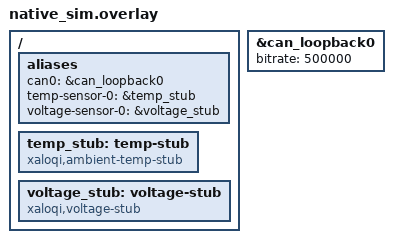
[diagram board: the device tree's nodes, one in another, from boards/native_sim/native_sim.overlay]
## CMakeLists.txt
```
# examples/sensor_ecu/CMakeLists.txt
# =============================================================================
# Xaloqi EDS — SensorECU example
# Zephyr zone controller with real sensor integration.
#
# BUILDING:
#   # Simulation build (CI / host testing, no hardware required):
#   # [EDS#339] -DEXTRA_CONF_FILE/-DDTC_OVERLAY_FILE must be passed
#   # explicitly — this example's own boards/native_sim/native_sim.conf
#   # and .overlay (nested) are never auto-discovered by Zephyr (only a
#   # flat boards/<board>.conf is — same gap O-132 found and documented
#   # for examples/bms_ecu/CMakeLists.txt). Omitting them silently builds
#   # without CONFIG_SENSOR/CONFIG_REBOOT and without the sensor devicetree
#   # nodes at all, rather than failing the way EDS#339 describes.
#   west build -b native_sim examples/sensor_ecu \
#     -- -DDIAG_SKIP_CODEGEN=ON \
#     -DEXTRA_CONF_FILE=<eds>/examples/sensor_ecu/boards/native_sim/native_sim.conf \
#     -DDTC_OVERLAY_FILE=<eds>/examples/sensor_ecu/boards/native_sim/native_sim.overlay
# =============================================================================

cmake_minimum_required(VERSION 3.20.0)

# [EDS#339] Out-of-tree devicetree bindings for the native_sim-only stub
# sensor driver (drivers/sensor_stub/) — must be appended before
# find_package(Zephyr) parses devicetree.
list(APPEND DTS_ROOT ${CMAKE_CURRENT_SOURCE_DIR})

# [#414] EDS Kconfig comes from this tree, not whichever EDS module the
# workspace has. Must precede find_package(Zephyr).
include(${CMAKE_CURRENT_SOURCE_DIR}/../../cmake/eds_zephyr_module.cmake)

find_package(Zephyr REQUIRED HINTS $ENV{ZEPHYR_BASE})

project(sensor_ecu
    VERSION     1.0.0
    LANGUAGES   C
    DESCRIPTION "SensorECU — Xaloqi EDS sensor integration example"
)

set(CMAKE_C_STANDARD          11)
set(CMAKE_C_STANDARD_REQUIRED ON)
set(CMAKE_C_EXTENSIONS        OFF)

# [#515] -Wundef (MISRA 20.9) below applies to EDS code only: Zephyr, module and
# HAL headers are system includes for this target. See the cmake file.
include(${CMAKE_CURRENT_SOURCE_DIR}/../../cmake/eds_third_party_headers.cmake)
eds_third_party_headers_are_system(app)

target_compile_options(app PRIVATE
    -Wall -Wextra -Wshadow -Wdouble-promotion -Wundef
    -Wno-unused-parameter -Wno-sign-conversion
    -fstack-usage
)

# ---------------------------------------------------------------------------
# Paths
# ---------------------------------------------------------------------------

set(DIAG_ROOT          "${CMAKE_CURRENT_SOURCE_DIR}/../..")
set(DIAG_CONFIG_YAML   "${CMAKE_CURRENT_SOURCE_DIR}/diagnostics_config.yaml")
set(DIAG_CODEGEN_SCRIPT "${DIAG_ROOT}/tools/codegen.py")
set(DIAG_GENERATED_DIR  "${CMAKE_CURRENT_SOURCE_DIR}/generated")
set(CODEGEN_SENTINEL    "${DIAG_GENERATED_DIR}/generated_config.h")

# [EDS#339] Defaulted ON for this example (the one difference from most
# other examples' CMakeLists.txt pattern, shared with vehicle_state_ecu).
# generated/did_handlers.c and generated/routine_handlers.c carry
# hand-written [APP HOOK] bodies that delegate to sensor_monitor.c's real
# state — did_entry_t.read_cb/write_cb and routine_entry_t's callbacks are
# bare function pointers copied by value into a fixed-capacity array at
# init (did_database_register()/routine_database_register()), so there is
# no way to re-point them at runtime; the callback bodies in the
# generated files are the only place this application's live behaviour
# can run. Re-running codegen would silently overwrite them with empty
# TODO stubs — the guard below fails loudly, at configure time, if that
# ever happens without the hooks being reapplied.
option(DIAG_SKIP_CODEGEN "Skip auto-running codegen (use existing generated/ files)" ON)

# ---------------------------------------------------------------------------
# Code generation
# ---------------------------------------------------------------------------

if(NOT DIAG_SKIP_CODEGEN)
    find_package(Python3 COMPONENTS Interpreter QUIET)
    if(NOT Python3_FOUND)
        message(FATAL_ERROR "Python3 not found. Install it or use -DDIAG_SKIP_CODEGEN=ON")
    endif()

    file(GLOB DIAG_TEMPLATES "${DIAG_ROOT}/tools/templates/*.j2")

    add_custom_command(
        OUTPUT   "${CODEGEN_SENTINEL}"
        COMMAND  "${Python3_EXECUTABLE}"
                 "${DIAG_CODEGEN_SCRIPT}"
                 --config "${DIAG_CONFIG_YAML}"
                 --out    "${DIAG_GENERATED_DIR}"
                 --safety-wrappers --asil-level B
                 --no-manifest
        DEPENDS
            "${DIAG_CONFIG_YAML}"
            "${DIAG_CODEGEN_SCRIPT}"
            ${DIAG_TEMPLATES}
        COMMENT "[sensor_ecu] Generating sources from diagnostics_config.yaml... "
                "NOTE: this will overwrite the hand-written [APP HOOK] bodies in "
                "generated/did_handlers.c and generated/routine_handlers.c -- "
                "reapply them before committing."
        VERBATIM
    )

    add_custom_target(run_codegen DEPENDS "${CODEGEN_SENTINEL}")
endif()

# ---------------------------------------------------------------------------
# Include paths
# ---------------------------------------------------------------------------

target_include_directories(app PRIVATE
    ${DIAG_ROOT}/core
    ${DIAG_ROOT}/core/uds_services
    ${DIAG_ROOT}/transport
    ${DIAG_ROOT}/config
    ${DIAG_ROOT}/platform
    ${DIAG_ROOT}/platform/zephyr
    ${DIAG_GENERATED_DIR}
    ${CMAKE_CURRENT_SOURCE_DIR}/src   # sensor_ecu.h
)

# ---------------------------------------------------------------------------
# Sources
# ---------------------------------------------------------------------------

# UDS service source list — set EDS_SERVICE_SRCS.
include(${DIAG_ROOT}/cmake/eds_service_sources.cmake)

target_sources(app PRIVATE

    # Application
    ${CMAKE_CURRENT_SOURCE_DIR}/src/main.c
    ${CMAKE_CURRENT_SOURCE_DIR}/src/sensor_monitor.c

    # [EDS#339] native_sim-only stub sensor driver backing the devicetree
    # nodes in boards/native_sim/native_sim.overlay (DTS_ROOT above).
    # Harmless to compile unconditionally: DEVICE_DT_INST_DEFINE expands
    # to nothing if no "xaloqi,ambient-temp-stub"/"xaloqi,voltage-stub"
    # node is status "okay" for the board being built.
    ${CMAKE_CURRENT_SOURCE_DIR}/drivers/sensor_stub/ambient_temp_stub.c
    ${CMAKE_CURRENT_SOURCE_DIR}/drivers/sensor_stub/voltage_stub.c

    # [#333] src/did_handlers_impl.c is deliberately NOT listed. It does not
    # exist in this example (only in sensor_ecu_freertos), and the generated
    # did_handlers.c below already defines did_handlers_register_all() and
    # s_did_table — listing both would be a duplicate-symbol link failure.
    # See sensor_ecu_freertos/CMakeLists.txt for the same hazard documented.

    # UDS core
    ${DIAG_ROOT}/core/uds_server.c
    ${DIAG_ROOT}/core/uds_session.c
    ${DIAG_ROOT}/core/uds_security.c
    ${DIAG_ROOT}/core/uds_safety.c
    ${DIAG_ROOT}/core/uds_security_algo.c
    ${DIAG_ROOT}/core/uds_access_table.c
    ${DIAG_ROOT}/core/uds_comm_control.c
    ${DIAG_ROOT}/core/uds_session_stats.c
    ${DIAG_ROOT}/core/uds_security_nvm.c
    ${DIAG_ROOT}/core/uds_aes_cmac.c
    ${DIAG_ROOT}/core/uds_transfer_ctx.c

    # UDS service handlers (all 16 SIDs + dispatch table).
    ${EDS_SERVICE_SRCS}

    # ISO-TP + CAN
    ${DIAG_ROOT}/transport/isotp.c
    ${DIAG_ROOT}/transport/can_transport.c
    ${DIAG_ROOT}/platform/zephyr/zephyr_can.c  # moved from transport/ — phase-housekeeping

    # Config databases
    ${DIAG_ROOT}/config/did_database.c
    ${DIAG_ROOT}/config/dtc_database.c
    ${DIAG_ROOT}/config/dtc_mirror.c
    ${DIAG_ROOT}/config/routine_database.c

    # Platform
    ${DIAG_ROOT}/platform/uds_flash_ops.c
    ${DIAG_ROOT}/platform/uds_image_policy.c  # [#232] Image verification policy singleton
    ${DIAG_ROOT}/platform/zephyr/zephyr_port.c
    ${DIAG_ROOT}/platform/zephyr/zephyr_mutex.c
    ${DIAG_ROOT}/platform/zephyr/zephyr_timer.c
    ${DIAG_ROOT}/platform/zephyr/zephyr_wdt.c
    ${DIAG_ROOT}/platform/zephyr/zephyr_platform_api.c

    # Generated
    ${DIAG_GENERATED_DIR}/did_handlers.c
    ${DIAG_GENERATED_DIR}/uds_init.c
    ${DIAG_GENERATED_DIR}/did_safety_wrappers.c
    ${DIAG_GENERATED_DIR}/routine_handlers.c
)

# NVM store — mock on native_sim, real NVS on hardware
if(CONFIG_BOARD_NATIVE_SIM)
    target_sources(app PRIVATE ${DIAG_ROOT}/platform/zephyr/nvm_store_mock.c)
else()
    target_sources(app PRIVATE ${DIAG_ROOT}/platform/zephyr/nvm_store.c)
endif()

if(NOT DIAG_SKIP_CODEGEN AND TARGET run_codegen)
    add_dependencies(app run_codegen)
endif()

# ---------------------------------------------------------------------------
# [APP HOOK] guard — fail loudly, at configure time, if generated/
# did_handlers.c or generated/routine_handlers.c were ever regenerated
# without reapplying the hand-written delegations to sensor_monitor.c.
# ---------------------------------------------------------------------------
file(STRINGS "${DIAG_GENERATED_DIR}/did_handlers.c" DIAG_DID_APP_HOOK_LINES
     REGEX "\\[APP HOOK\\]")
list(LENGTH DIAG_DID_APP_HOOK_LINES DIAG_DID_APP_HOOK_COUNT)
if(DIAG_DID_APP_HOOK_COUNT LESS 5)
    message(FATAL_ERROR
        "\n"
        "[sensor_ecu] ERROR: generated/did_handlers.c is missing its\n"
        "       [APP HOOK] markers (found ${DIAG_DID_APP_HOOK_COUNT}, expected >= 5).\n"
        "       This file was regenerated and the hand-written delegations to\n"
        "       sensor_monitor.c were lost. See EDS#339 and reapply them\n"
        "       before building.\n"
    )
endif()

file(STRINGS "${DIAG_GENERATED_DIR}/routine_handlers.c" DIAG_RTN_APP_HOOK_LINES
     REGEX "\\[APP HOOK\\]")
list(LENGTH DIAG_RTN_APP_HOOK_LINES DIAG_RTN_APP_HOOK_COUNT)
if(DIAG_RTN_APP_HOOK_COUNT LESS 2)
    message(FATAL_ERROR
        "\n"
        "[sensor_ecu] ERROR: generated/routine_handlers.c is missing its\n"
        "       [APP HOOK] markers (found ${DIAG_RTN_APP_HOOK_COUNT}, expected >= 2).\n"
        "       This file was regenerated and the hand-written delegations to\n"
        "       sensor_monitor.c were lost. See EDS#339 and reapply them\n"
        "       before building.\n"
    )
endif()

# Suppress the uds_msg_buf_t _Static_assert for all Zephyr example builds.
# The Zephyr task stacks for these examples (4096-6144 bytes) are large enough
# to hold the struct if needed, but all EDS stack buffers are module-level
# statics — the assert would fire as a false positive on every compilation unit.
# Zephyr's native_sim gets this via the CMakeLists.txt native_sim block;
# hardware targets need it here.
target_compile_definitions(app PRIVATE EDS_MSG_BUF_MAX_STACK_BYTES=8192)
```

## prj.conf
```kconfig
# examples/sensor_ecu/prj.conf
# Base configuration for all board targets.
# Board-specific overrides in boards/<board>/<board>.conf

# --- CAN driver ---
CONFIG_CAN=y
CONFIG_CAN_INIT_PRIORITY=80
CONFIG_STATS=y
CONFIG_CAN_STATS=y

# --- Sensor subsystem ---
CONFIG_SENSOR=y
CONFIG_I2C=y

# --- Kernel / threading ---
CONFIG_MULTITHREADING=y
CONFIG_THREAD_STACK_INFO=y
CONFIG_THREAD_NAME=y

# --- Tick rate: 1 ms for ISO-TP ---
CONFIG_SYS_CLOCK_TICKS_PER_SEC=1000
CONFIG_TICKLESS_KERNEL=n

# --- Watchdog ---
CONFIG_WATCHDOG=y
CONFIG_WDT_DISABLE_AT_BOOT=n
CONFIG_DIAG_WDT_WINDOW_MS=100

# --- Logging ---
CONFIG_LOG=y
CONFIG_LOG_DEFAULT_LEVEL=3
CONFIG_LOG_BACKEND_UART=y
CONFIG_LOG_BUFFER_SIZE=2048

# --- Safety hardening ---
CONFIG_ASSERT=y
CONFIG_STACK_CANARIES=y
# Fail the build if the canaries are not real (see Kconfig EDS_REQUIRE_STACK_CANARIES).
CONFIG_EDS_REQUIRE_STACK_CANARIES=y
CONFIG_STACK_SENTINEL=y

# --- No heap (MISRA-21.3) ---
CONFIG_HEAP_MEM_POOL_SIZE=0

# --- C library ---
CONFIG_NEWLIB_LIBC=y
# [#498] Fail the build, rather than silently link picolibc, if newlib is unavailable.
CONFIG_EDS_REQUIRE_NEWLIB=y

# --- UDS session timing / SecurityAccess lockout: diagnostics_config.yaml (EDS#455);
#     ISO-TP timeouts: EDS defaults, ISO 15765-2:2024 1000 ms (EDS#453) ---

# --- Task stack sizes ---
CONFIG_DIAG_TASK_STACK_SIZE=4096
CONFIG_DIAG_TASK_PRIORITY=5

# --- Build output ---
CONFIG_BUILD_OUTPUT_BIN=y
CONFIG_BUILD_OUTPUT_HEX=y
```

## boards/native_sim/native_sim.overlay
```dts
/*
 * =============================================================================
 * Xaloqi EDS
 * boards/native_sim/native_sim.overlay
 * examples/sensor_ecu/
 *
 * Device Tree overlay for native_sim (host simulation).
 *
 * Provides:
 *   - CAN loopback (same as all other examples)
 *   - Two stub sensor nodes, backed by a minimal out-of-tree driver that
 *     ships with this example (drivers/sensor_stub/, bound via
 *     dts/bindings/sensor/ -- see CMakeLists.txt's DTS_ROOT addition).
 *     [EDS#339] These return fixed nominal readings; native_sim has no
 *     physical sensor to simulate, and DTC firing/clearing is
 *     demonstrated via extreme thresholds (DID 0xD010/0xD011), not by
 *     varying the reading -- see sensor_monitor.c's header comment.
 *
 * On real hardware, replace these nodes with your physical sensor:
 *
 *   Temperature sensor examples:
 *     SHTC3 (I2C):   compatible = "sensirion,shtc3";
 *     LM75A (I2C):   compatible = "lm75";
 *     MCP9808 (I2C): compatible = "microchip,mcp9808";
 *     NTC on ADC:    compatible = "ntc-thermistor-generic";
 *
 *   Voltage sensor examples:
 *     INA219 (I2C):  compatible = "ti,ina219";
 *     ADC divider:   compatible = "voltage-divider";
 *
 * The aliases (temp-sensor-0, voltage-sensor-0) are the only coupling
 * between sensor_monitor.c and the board DTS. Change the alias target
 * to point at your physical sensor node and the application code is
 * unchanged.
 * =============================================================================
 */

/ {
    aliases {
        /* CAN loopback — same as basic_ecu */
        can0 = &can_loopback0;

        /*
         * Sensor aliases — sensor_monitor.c resolves devices by these names.
         * On native_sim: point to stub driver nodes below.
         * On hardware: point to the physical sensor node in your board DTS.
         */
        temp-sensor-0    = &temp_stub;
        voltage-sensor-0 = &voltage_stub;
    };

    /*
     * [EDS#339] Backed by drivers/sensor_stub/ambient_temp_stub.c — fixed
     * 25 degC reading. Previously used compatible = "zephyr,temperature-
     * stub", a string that both claimed in-tree Zephyr provenance it
     * didn't have and had no backing driver at all (undefined reference
     * to __device_dts_ord_N at link time). Renamed to an "xaloqi,"
     * compatible matching the binding this example actually ships.
     */
    temp_stub: temp-stub {
        compatible = "xaloqi,ambient-temp-stub";
        status = "okay";
    };

    /* [EDS#339] Same history and fix as temp_stub above. */
    voltage_stub: voltage-stub {
        compatible = "xaloqi,voltage-stub";
        status = "okay";
    };
};

&can_loopback0 {
    status = "okay";
    bitrate   = <500000>;
};
```

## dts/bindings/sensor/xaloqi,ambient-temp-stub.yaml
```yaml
# Copyright (c) 2026 Xaloqi
# SPDX-License-Identifier: Apache-2.0

description: |
  Xaloqi EDS example-only stub ambient temperature sensor.

  native_sim has no real temperature hardware. This binding backs a
  minimal out-of-tree driver (drivers/sensor_stub/ambient_temp_stub.c)
  that returns a fixed nominal reading so sensor_monitor.c's real Zephyr
  sensor API calls (sensor_sample_fetch/sensor_channel_get) have an
  actual struct device to resolve against on native_sim. On real
  hardware, replace this node with a physical sensor binding (see
  boards/native_sim/native_sim.overlay's header comment for examples) —
  this binding is not meant to be used outside this example.

compatible: "xaloqi,ambient-temp-stub"

include: sensor-device.yaml
```

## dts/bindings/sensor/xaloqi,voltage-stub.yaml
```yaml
# Copyright (c) 2026 Xaloqi
# SPDX-License-Identifier: Apache-2.0

description: |
  Xaloqi EDS example-only stub supply-voltage sensor.

  native_sim has no real voltage-monitoring hardware. This binding backs
  a minimal out-of-tree driver (drivers/sensor_stub/voltage_stub.c) that
  returns a fixed nominal reading so sensor_monitor.c's real Zephyr
  sensor API calls (sensor_sample_fetch/sensor_channel_get) have an
  actual struct device to resolve against on native_sim. On real
  hardware, replace this node with a physical sensor binding (see
  boards/native_sim/native_sim.overlay's header comment for examples) —
  this binding is not meant to be used outside this example.

compatible: "xaloqi,voltage-stub"

include: sensor-device.yaml
```

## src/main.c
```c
/*
 * =============================================================================
 * Xaloqi EDS
 * FILE: examples/sensor_ecu/src/main.c
 *
 * PURPOSE: SensorECU — zone controller with real sensor integration.
 *
 *          Demonstrates the complete Xaloqi EDS sensor pattern:
 *
 *            Zephyr sensor API (temp, voltage)
 *              ↓
 *            sensor_monitor thread (100 ms cycle)
 *              ↓ dtc_database_set_status()
 *            DTC database (0xD00101, 0xD00102, 0xD00201, 0xD00202)
 *              ↓
 *            UDS 0x19 ReadDTCInformation → tester reads active faults
 *            UDS 0x22 ReadDataByIdentifier → tester reads live sensor values
 *
 *          Two threads run concurrently:
 *            diag_task     — 1 ms poll loop (ISO-TP + UDS dispatch)
 *            sensor_monitor — 100 ms sensor read + DTC update
 *
 * THREAD MODEL:
 *   main()
 *     ├─ sensor_monitor_init()   → starts sensor_monitor thread
 *     ├─ uds_generated_init()    → initialises UDS stack
 *     └─ diag task created       → starts diagnostic poll loop
 *
 *   sensor_monitor thread (priority 7, 100 ms sleep):
 *     sensor_sample_fetch() → dtc_database_set_status() → k_mutex_unlock()
 *
 *   diag_task thread (priority 5, 1 ms tick):
 *     can_transport_receive() → isotp_process_rx_frame() → uds_server_process_request()
 *     DID 0xD001/0xD002/0xD003 handlers — generated/did_handlers.c's
 *     [APP HOOK] bodies call sensor_state_get() directly [EDS#339, fixed].
 *     See sensor_monitor.c's header comment for the native_sim driver.
 *
 * SPDX-License-Identifier: Apache-2.0
 * =============================================================================
 */

#include "sensor_ecu.h"
#include "uds_types.h"
#include "uds_server.h"
#include "uds_periodic.h"
#include "uds_session.h"
#include "dtc_database.h"
#include "isotp.h"
#include "can_transport.h"
#include "zephyr_port.h"
#include "zephyr_mutex.h"
#include "zephyr_timer.h"
#include "zephyr_wdt.h"
#include "nvm_store.h"
#include "uds_init.h"
#include "uds_security_algo.h"
#include "generated_config.h"

#include <zephyr/kernel.h>
#include <zephyr/device.h>
#include <zephyr/drivers/can.h>
#include <zephyr/logging/log.h>

LOG_MODULE_REGISTER(sensor_ecu, LOG_LEVEL_INF);

/* ---------------------------------------------------------------------------
 * Configuration
 * ---------------------------------------------------------------------------*/

#define DIAG_CAN_DEV            DEVICE_DT_GET(DT_ALIAS(can0))
#define DIAG_RX_CAN_ID          ((uint32_t)GEN_CAN_RX_ID)
#define DIAG_TX_CAN_ID          ((uint32_t)GEN_CAN_TX_ID)

#ifndef CONFIG_DIAG_TASK_STACK_SIZE
#define CONFIG_DIAG_TASK_STACK_SIZE  (4096U)
#endif

#ifndef CONFIG_DIAG_TASK_PRIORITY
#define CONFIG_DIAG_TASK_PRIORITY    (5)
#endif

#define DIAG_OVERRUN_LOG_THRESHOLD   (3U)

/* ---------------------------------------------------------------------------
 * Static allocations
 * ---------------------------------------------------------------------------*/

K_THREAD_STACK_DEFINE(s_diag_stack, CONFIG_DIAG_TASK_STACK_SIZE);
static struct k_thread s_diag_thread;

static uds_msg_buf_t s_req_buf;
static uds_msg_buf_t s_resp_buf;

static diag_mutex_t s_session_lock;
static diag_mutex_t s_security_lock;
static diag_timer_t s_tick_timer;
static diag_wdt_t   s_wdt;

/* [EDS#354] Dedicated lock for config/dtc_database.c's critical sections —
 * separate from s_session_lock/s_security_lock (not the same concern,
 * and holding the DTC lock should never block the UDS dispatch path on
 * session/security state or vice versa). sensor_monitor's thread calls
 * dtc_database_set_status() independently of diag_task's UDS dispatch,
 * which calls into the same database via SID 0x19/0x14 — config/
 * dtc_database.c has no internal locking of its own (it's platform-
 * agnostic by design), so this example must supply it. See
 * dtc_database_set_lock_callbacks()'s own doc comment. */
static diag_mutex_t s_dtc_lock;

static void dtc_lock_cb(void)
{
    (void)diag_mutex_lock(&s_dtc_lock);
}

static void dtc_unlock_cb(void)
{
    (void)diag_mutex_unlock(&s_dtc_lock);
}

/* ---------------------------------------------------------------------------
 * TRNG callback (same pattern as basic_ecu)
 * ---------------------------------------------------------------------------*/

#if defined(CONFIG_ENTROPY_GENERATOR)
#include <zephyr/drivers/entropy.h>
static const struct device *s_entropy_dev = NULL;

static uds_status_t diag_trng_cb(uint8_t *buf, uint8_t len)
{
    if ((s_entropy_dev == NULL) || !device_is_ready(s_entropy_dev)) {
        return UDS_STATUS_ERR_PLATFORM;
    }
    int rc = entropy_get_entropy(s_entropy_dev, buf, (size_t)len);
    return (rc == 0) ? UDS_STATUS_OK : UDS_STATUS_ERR_PLATFORM;
}
#endif

static int diag_security_algo_init(void)
{
#if defined(CONFIG_ENTROPY_GENERATOR)
    s_entropy_dev = DEVICE_DT_GET(DT_CHOSEN(zephyr_entropy));
    if (!device_is_ready(s_entropy_dev)) {
        LOG_WRN("TRNG not ready — LFSR fallback.");
        s_entropy_dev = NULL;
    } else {
        uds_security_algo_set_rng_cb(diag_trng_cb);
        LOG_INF("TRNG: %s", s_entropy_dev->name);
    }
#else
    LOG_WRN("No entropy device — LFSR fallback (dev/CI only).");
#endif
    LOG_WRN("Placeholder AES keys active — inject OEM keys before production.");
    return 0;
}

/* ---------------------------------------------------------------------------
 * ISO-TP RX completion callback
 * ---------------------------------------------------------------------------*/

static void on_isotp_rx_complete(const uint8_t *data, uint32_t length, void *arg)
{
    uds_server_ctx_t *srv = (uds_server_ctx_t *)arg;
    isotp_ctx_t      *tp  = uds_generated_get_isotp();
    uds_status_t      status;
    uint16_t          i;

    if ((data == NULL) || (srv == NULL) || (tp == NULL)) {
        return;
    }
    if ((length == 0U) || (length > (uint32_t)UDS_MAX_PAYLOAD_LEN)) {
        return;
    }

    for (i = 0U; i < (uint16_t)length; i++) {
        s_req_buf.data[i] = data[i];
    }
    s_req_buf.length  = (uint16_t)length;
    s_resp_buf.length = 0U;

    (void)diag_mutex_lock(&s_session_lock);
    (void)diag_mutex_lock(&s_security_lock);
    /* [EDS-toolchain#165] A functional request (ISO 15765-4) must not draw
     * the NRCs ISO 14229-1 Table 4 says to suppress. */
    uds_addressing_t addressing = UDS_ADDRESSING_PHYSICAL;
    (void)isotp_get_rx_addressing(tp, &addressing);
    status = uds_server_process_request_ex(srv, &s_req_buf, &s_resp_buf, addressing);
    (void)diag_mutex_unlock(&s_security_lock);
    (void)diag_mutex_unlock(&s_session_lock);

    if (s_resp_buf.length > 0U) {
        (void)isotp_transmit(tp, s_resp_buf.data, s_resp_buf.length);
    } else if (status != UDS_STATUS_OK) {
        LOG_ERR("UDS error 0x%02X, no response.", (unsigned)status);
    }

    /* [P2-0x11-01] Deferred reset: response is on the wire, now reset. */
    if (srv->pending_reset_type != (uint8_t)0U) {
        uint8_t reset_type = srv->pending_reset_type;
        srv->pending_reset_type = (uint8_t)0U;
        (void)zephyr_port_nvm_flush();
        k_msleep(50);  /* Allow ISO-TP TX to reach the wire before reset (As timer). */
        (void)zephyr_port_ecu_reset(reset_type);
        /* Does not return. */
    }
}

/* ---------------------------------------------------------------------------
 * 1 ms tick
 * ---------------------------------------------------------------------------*/

typedef struct { uds_server_ctx_t *srv; isotp_ctx_t *tp; } tick_ctx_t;

static void on_tick(void *arg)
{
    tick_ctx_t *ctx = (tick_ctx_t *)arg;
    if ((ctx == NULL) || (ctx->tp == NULL) || (ctx->srv == NULL)) { return; }
    (void)isotp_tick_1ms(ctx->tp);
    (void)diag_mutex_lock(&s_session_lock);
    (void)diag_mutex_lock(&s_security_lock);
    (void)uds_server_tick_1ms(ctx->srv);
    (void)uds_periodic_tick_1ms();
    (void)diag_mutex_unlock(&s_security_lock);
    (void)diag_mutex_unlock(&s_session_lock);
}

/* ---------------------------------------------------------------------------
 * Diagnostics task
 * ---------------------------------------------------------------------------*/

static void diag_task_entry(void *p1, void *p2, void *p3)
{
    uds_server_ctx_t *srv = (uds_server_ctx_t *)p1;
    can_transport_t  *can = (can_transport_t  *)p2;
    isotp_ctx_t      *tp  = (isotp_ctx_t      *)p3;

    uds_status_t    status;
    uds_can_frame_t rx_frame;
    bool            frame_ready;
    uint32_t        overrun_count;
    uint32_t        prev_overrun = 0U;

    tick_ctx_t tick_ctx = { .srv = srv, .tp = tp };

    LOG_INF("Diagnostics task started.");

    if (diag_timer_start(&s_tick_timer) != UDS_STATUS_OK) {
        LOG_ERR("Timer start failed.");
        return;
    }

    while (true) {
        status = diag_timer_wait_tick(&s_tick_timer, 2U);
        if (status == UDS_STATUS_ERR_TIMEOUT) {
            LOG_WRN("1 ms tick timeout.");
        }

        /* [EDS#558] Drain every queued frame, at most the queue depth. The Flow
         * Control BlockSize keeps a burst within the RX queue only if each
         * iteration empties it; one frame per tick loses CFs of long requests. */
        frame_ready = true;
        for (uint32_t rx_n = 0U;
             frame_ready && (rx_n < (uint32_t)EDS_CAN_RX_QUEUE_DEPTH); rx_n++) {
            frame_ready = false;
            status = can_transport_receive(can, &rx_frame, &frame_ready);

            if (status == UDS_STATUS_ERR_CAN_BUS_OFF) {
                LOG_ERR("CAN bus-off.");
            } else if ((status == UDS_STATUS_OK) && frame_ready) {
                (void)isotp_process_rx_frame(tp, &rx_frame,
                                              on_isotp_rx_complete, (void *)srv);
            }
        }

        on_tick(&tick_ctx);

        {
            static uds_msg_buf_t s_periodic_frame;
            while (uds_periodic_pop_due(&s_periodic_frame) == UDS_STATUS_OK) {
                /* [EDS#546] A periodic message is a UUDT frame on its own CAN ID
                 * (ISO 14229-3 §8.5): it bypasses the ISO-TP channel, so it can
                 * go out while a multi-frame response is being sent.
                 * [EDS#194] Re-queue if the CAN driver refuses it instead of
                 * silently dropping this period; retry on the next 1ms tick and
                 * stop draining this tick. */
                if (isotp_transmit_uudt(tp, s_periodic_frame.data,
                                   (uint32_t)s_periodic_frame.length) != UDS_STATUS_OK) {
                    (void)uds_periodic_requeue_last();
                    break;
                }
            }
        }

        (void)diag_wdt_feed(&s_wdt);

        (void)diag_timer_pending_ticks(&s_tick_timer, &overrun_count);
        if ((overrun_count - prev_overrun) >= DIAG_OVERRUN_LOG_THRESHOLD) {
            LOG_WRN("Poll loop overrun: %u ticks missed.",
                    (unsigned)(overrun_count - prev_overrun));
            prev_overrun = overrun_count;
        }
    }
}

static void s_on_session_change(uds_session_type_t old_sess,
                                uds_session_type_t new_sess)
{
    (void)old_sess;
    if (new_sess == UDS_SESSION_DEFAULT) {
        (void)uds_periodic_cancel_all();
    }
}

/* ---------------------------------------------------------------------------
 * main()
 * ---------------------------------------------------------------------------*/

int main(void)
{
    uds_status_t      status;
    can_transport_t  *can = NULL;
    uds_server_ctx_t *srv = NULL;
    isotp_ctx_t      *tp  = NULL;

    LOG_INF("=============================================================");
    LOG_INF("Xaloqi EDS  v" GEN_ECU_VERSION "  —  SensorECU");
    LOG_INF("  DIDs: %u   DTCs: %u",
            (unsigned)GEN_DID_COUNT, (unsigned)GEN_DTC_COUNT);
    LOG_INF("  RX: 0x%03X   TX: 0x%03X",
            (unsigned)DIAG_RX_CAN_ID, (unsigned)DIAG_TX_CAN_ID);
    LOG_INF("=============================================================");

    /* ── Mutex init ──────────────────────────────────────────────────────── */
    if ((diag_mutex_init(&s_session_lock)  != UDS_STATUS_OK) ||
        (diag_mutex_init(&s_security_lock) != UDS_STATUS_OK) ||
        (diag_mutex_init(&s_dtc_lock)       != UDS_STATUS_OK)) {
        LOG_ERR("Mutex init failed.");
        return -1;
    }

    /* [EDS#354] Must be registered before sensor_monitor_init() starts the
     * sensor_monitor thread below — that thread calls dtc_database_set_status()
     * as soon as its first 100 ms cycle elapses. */
    dtc_database_set_lock_callbacks(dtc_lock_cb, dtc_unlock_cb);

    /* ── Sensor monitor (starts sensor_monitor thread) ───────────────────── */
    sensor_monitor_init();
    LOG_INF("Sensor monitor initialised.");

    /* ── Watchdog ────────────────────────────────────────────────────────── */
    (void)diag_wdt_init(&s_wdt);

    /* ── Timer ───────────────────────────────────────────────────────────── */
    status = diag_timer_init(&s_tick_timer, on_tick, NULL);
    if (status != UDS_STATUS_OK) {
        LOG_ERR("Timer init failed.");
        return -1;
    }

    /* ── CAN transport ───────────────────────────────────────────────────── */
    const zephyr_port_cfg_t port_cfg = {
        .can_dev        = DIAG_CAN_DEV,
        .physical_rx_id = DIAG_RX_CAN_ID,   /* alongside the 0x7DF functional filter */
    };
    status = zephyr_port_init(&port_cfg, &can);
    if (status != UDS_STATUS_OK) {
        LOG_ERR("Platform init failed.");
        return -1;
    }

    /* ── NVM store ───────────────────────────────────────────────────────── */
    /*
     * [EDS#200] Must run before uds_generated_init() (dtc_mirror_init() at
     * Step 3.5 sits on top of nvm_store and silently no-ops until this
     * succeeds). This example only targets native_sim, where
     * platform/zephyr/nvm_store_mock.c (RAM-backed) is linked instead of
     * the real NVS backend — its nvm_store_init() ignores cfg entirely, so
     * NULL is correct here (see nvm_store.h: "may be NULL on host").
     */
    status = nvm_store_init(NULL);
    if (status != UDS_STATUS_OK) {
        LOG_ERR("NVM store init failed: 0x%02X — DTC mirror will not "
                "survive reset this run.", (unsigned)status);
    }

    /* ── Security algo ───────────────────────────────────────────────────── */
    (void)diag_security_algo_init();

    /* ── UDS stack ───────────────────────────────────────────────────────── */
    status = uds_generated_init(can, DIAG_RX_CAN_ID, DIAG_TX_CAN_ID);
    if (status != UDS_STATUS_OK) {
        LOG_ERR("UDS init failed: 0x%02X", (unsigned)status);
        return -1;
    }

    srv = uds_generated_get_server();
    tp  = uds_generated_get_isotp();

    if ((srv == NULL) || (tp == NULL)) {
        LOG_ERR("NULL context after init.");
        return -1;
    }

    (void)uds_periodic_init();
    (void)uds_session_register_change_cb(srv->cfg.session_ctx,
                                          s_on_session_change);

    LOG_INF("UDS stack ready. Sensor DIDs: 0xD001 (temp), 0xD002 (voltage), 0xD003 (status)");
    LOG_INF("Active DTCs visible via UDS 0x19 subfunction 0x02.");

    /* ── Diagnostics thread ──────────────────────────────────────────────── */
    (void)k_thread_create(
        &s_diag_thread, s_diag_stack,
        K_THREAD_STACK_SIZEOF(s_diag_stack),
        diag_task_entry,
        (void *)srv, (void *)can, (void *)tp,
        CONFIG_DIAG_TASK_PRIORITY, 0U, K_NO_WAIT
    );
    k_thread_name_set(&s_diag_thread, "diag_task");

    LOG_INF("SensorECU running.");
    return 0;
}
```

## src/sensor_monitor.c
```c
/*
 * =============================================================================
 * Xaloqi EDS
 * FILE: examples/sensor_ecu/src/sensor_monitor.c
 *
 * PURPOSE: Sensor monitoring thread — reads temperature and voltage sensors
 *          via the Zephyr sensor API every 100 ms, checks thresholds, and
 *          updates DTC status via dtc_database_set_status().
 *
 * SENSOR INTEGRATION PATTERN:
 *
 *   1. Declare sensor device handles using DT_ALIAS.
 *      The board overlay maps physical sensor nodes to well-known aliases:
 *        temp-sensor-0   → on-board temperature sensor
 *        voltage-sensor-0 → supply voltage monitor
 *
 *   2. On each monitor cycle:
 *      a. sensor_sample_fetch()  — trigger a new measurement
 *      b. sensor_channel_get()   — read the measured value
 *      c. Apply threshold logic  — compare to fault limits
 *      d. dtc_database_set_status() — set/clear DTCs based on result
 *
 *   3. The latest readings are stored in s_sensor_state (protected by
 *      s_sensor_lock). sensor_state_get() below is called directly from
 *      the [APP HOOK] bodies in generated/did_handlers.c's DID
 *      0xD001/0xD002/0xD003 read callbacks and generated/
 *      routine_handlers.c's SensorSelfTest routine — [EDS#339], fixed.
 *      The threshold setters below (sensor_set_temp_threshold_high/low)
 *      are likewise called from DID 0xD010/0xD011's write callbacks and
 *      the ResetSensorCalibration routine.
 *
 * NATIVE_SIM BEHAVIOUR [EDS#339, fixed]:
 *   The board overlay declares devicetree nodes with
 *   compatible = "xaloqi,ambient-temp-stub" / "xaloqi,voltage-stub",
 *   backed by a minimal driver this example ships
 *   (drivers/sensor_stub/ambient_temp_stub.c, voltage_stub.c — see
 *   CMakeLists.txt's DTS_ROOT addition for how the binding is found).
 *   Both return a fixed nominal reading (25 degC, 12.0 V) rather than
 *   anything dynamic: native_sim has no physical sensor to simulate, and
 *   DTC firing/clearing is demonstrated via extreme thresholds on DID
 *   0xD010/0xD011, not by varying the reading. See EDS#339 for the full
 *   history (this previously failed to link — no backing driver existed
 *   at all).
 *
 * FREERTOS ADAPTATION NOTE:
 *   On FreeRTOS, replace:
 *     sensor_sample_fetch()      → your_adc_read() or vendor HAL call
 *     sensor_channel_get()       → scale raw ADC counts to engineering units
 *     dtc_database_set_status()  → same call (platform-independent)
 *   The threshold logic and DTC update calls are identical on both platforms.
 *
 * SPDX-License-Identifier: Apache-2.0
 * =============================================================================
 */

#include "sensor_ecu.h"
#include "dtc_database.h"

#include <zephyr/kernel.h>
#include <zephyr/device.h>
#include <zephyr/drivers/sensor.h>
#include <zephyr/logging/log.h>

LOG_MODULE_REGISTER(sensor_monitor, LOG_LEVEL_INF);

/* ---------------------------------------------------------------------------
 * Sensor monitor thread configuration
 * ---------------------------------------------------------------------------*/

#define SENSOR_MONITOR_STACK_SIZE   (1024U)
#define SENSOR_MONITOR_PRIORITY     (7)        /* lower priority than diag task */
#define SENSOR_MONITOR_INTERVAL_MS  (100U)     /* sample every 100 ms */

K_THREAD_STACK_DEFINE(s_monitor_stack, SENSOR_MONITOR_STACK_SIZE);
static struct k_thread s_monitor_thread;

/* ---------------------------------------------------------------------------
 * Sensor device handles
 *
 * These are resolved from Device Tree aliases defined in the board overlay.
 * On native_sim the aliases point to devicetree nodes with no backing
 * driver in this tree — see the NATIVE_SIM BEHAVIOUR note above [EDS#339],
 * this currently fails to link, not just to run. On real hardware they
 * point to the physical sensor driver nodes.
 *
 * DT_ALIAS resolves at compile time — if the alias is absent from the DTS,
 * the build fails with a clear error (missing alias 'temp-sensor-0').
 * ---------------------------------------------------------------------------*/

static const struct device *s_temp_dev    = NULL;
static const struct device *s_voltage_dev = NULL;

/* ---------------------------------------------------------------------------
 * Shared sensor state + mutex
 * ---------------------------------------------------------------------------*/

static sensor_state_t s_sensor_state;
static struct k_mutex s_sensor_lock;

/* ---------------------------------------------------------------------------
 * DTC codes — must match diagnostics_config.yaml
 * ---------------------------------------------------------------------------*/

#define DTC_TEMP_HIGH     (0xD00101UL)
#define DTC_TEMP_LOW      (0xD00102UL)
#define DTC_VOLTAGE_HIGH  (0xD00201UL)
#define DTC_VOLTAGE_LOW   (0xD00202UL)

/* ---------------------------------------------------------------------------
 * Internal: read temperature from Zephyr sensor driver
 * Returns true on success, false if sensor unavailable.
 * ---------------------------------------------------------------------------*/

static bool read_temperature(int16_t *out_deg_c)
{
    struct sensor_value val;
    int rc;

    if ((s_temp_dev == NULL) || !device_is_ready(s_temp_dev)) {
        return false;
    }

    rc = sensor_sample_fetch(s_temp_dev);
    if (rc != 0) {
        LOG_WRN("Temperature fetch failed: %d", rc);
        return false;
    }

    rc = sensor_channel_get(s_temp_dev, SENSOR_CHAN_AMBIENT_TEMP, &val);
    if (rc != 0) {
        LOG_WRN("Temperature channel read failed: %d", rc);
        return false;
    }

    /* sensor_value: val1 = integer part (°C), val2 = fractional (millionths) */
    *out_deg_c = (int16_t)val.val1;
    return true;
}

/* ---------------------------------------------------------------------------
 * Internal: read supply voltage from Zephyr sensor driver
 * Returns true on success, false if sensor unavailable.
 * ---------------------------------------------------------------------------*/

static bool read_voltage(uint16_t *out_mv)
{
    struct sensor_value val;
    int rc;

    if ((s_voltage_dev == NULL) || !device_is_ready(s_voltage_dev)) {
        return false;
    }

    rc = sensor_sample_fetch(s_voltage_dev);
    if (rc != 0) {
        LOG_WRN("Voltage fetch failed: %d", rc);
        return false;
    }

    rc = sensor_channel_get(s_voltage_dev, SENSOR_CHAN_VOLTAGE, &val);
    if (rc != 0) {
        LOG_WRN("Voltage channel read failed: %d", rc);
        return false;
    }

    /*
     * Zephyr voltage channel returns volts.
     * val1 = integer volts, val2 = fractional part in millionths.
     * Convert to mV: (val1 * 1000) + (val2 / 1000).
     */
    int32_t mv = (val.val1 * 1000) + (val.val2 / 1000);
    *out_mv = (uint16_t)((mv < 0) ? 0 : (uint32_t)mv);
    return true;
}

/* ---------------------------------------------------------------------------
 * Internal: check thresholds and update DTC status
 * ---------------------------------------------------------------------------*/

static void check_thresholds(sensor_state_t *state)
{
    /* ── Temperature faults ─────────────────────────────────────────────── */
    if (state->status & SENSOR_STATUS_TEMP_OK) {

        if (state->temp_deg_c > (int16_t)state->temp_threshold_high_deg_c) {
            state->status |= SENSOR_STATUS_TEMP_FAULT_HIGH;
            state->status &= ~(uint8_t)SENSOR_STATUS_TEMP_FAULT_LOW;
            (void)dtc_database_set_status(DTC_TEMP_HIGH, true);
            (void)dtc_database_set_status(DTC_TEMP_LOW,  false);
            LOG_WRN("TEMP HIGH fault: %d °C > %d °C threshold",
                    (int)state->temp_deg_c,
                    (int)state->temp_threshold_high_deg_c);

        } else if (state->temp_deg_c < (int16_t)state->temp_threshold_low_deg_c) {
            state->status |= SENSOR_STATUS_TEMP_FAULT_LOW;
            state->status &= ~(uint8_t)SENSOR_STATUS_TEMP_FAULT_HIGH;
            (void)dtc_database_set_status(DTC_TEMP_LOW,  true);
            (void)dtc_database_set_status(DTC_TEMP_HIGH, false);
            LOG_WRN("TEMP LOW fault: %d °C < %d °C threshold",
                    (int)state->temp_deg_c,
                    (int)state->temp_threshold_low_deg_c);

        } else {
            /* In-range — clear both temp faults */
            state->status &= ~(uint8_t)(SENSOR_STATUS_TEMP_FAULT_HIGH |
                                         SENSOR_STATUS_TEMP_FAULT_LOW);
            (void)dtc_database_set_status(DTC_TEMP_HIGH, false);
            (void)dtc_database_set_status(DTC_TEMP_LOW,  false);
        }
    }

    /* ── Voltage faults ─────────────────────────────────────────────────── */
    if (state->status & SENSOR_STATUS_VOLTAGE_OK) {

        if (state->voltage_mv > SENSOR_VOLTAGE_NOMINAL_HIGH_MV) {
            state->status |= SENSOR_STATUS_VOLTAGE_FAULT_HIGH;
            state->status &= ~(uint8_t)SENSOR_STATUS_VOLTAGE_FAULT_LOW;
            (void)dtc_database_set_status(DTC_VOLTAGE_HIGH, true);
            (void)dtc_database_set_status(DTC_VOLTAGE_LOW,  false);
            LOG_WRN("VOLTAGE HIGH fault: %u mV > %u mV",
                    (unsigned)state->voltage_mv,
                    (unsigned)SENSOR_VOLTAGE_NOMINAL_HIGH_MV);

        } else if (state->voltage_mv < SENSOR_VOLTAGE_NOMINAL_LOW_MV) {
            state->status |= SENSOR_STATUS_VOLTAGE_FAULT_LOW;
            state->status &= ~(uint8_t)SENSOR_STATUS_VOLTAGE_FAULT_HIGH;
            (void)dtc_database_set_status(DTC_VOLTAGE_LOW,  true);
            (void)dtc_database_set_status(DTC_VOLTAGE_HIGH, false);
            LOG_WRN("VOLTAGE LOW fault: %u mV < %u mV",
                    (unsigned)state->voltage_mv,
                    (unsigned)SENSOR_VOLTAGE_NOMINAL_LOW_MV);

        } else {
            /* In-range — clear both voltage faults */
            state->status &= ~(uint8_t)(SENSOR_STATUS_VOLTAGE_FAULT_HIGH |
                                         SENSOR_STATUS_VOLTAGE_FAULT_LOW);
            (void)dtc_database_set_status(DTC_VOLTAGE_HIGH, false);
            (void)dtc_database_set_status(DTC_VOLTAGE_LOW,  false);
        }
    }
}

/* ---------------------------------------------------------------------------
 * Sensor monitor thread entry
 * ---------------------------------------------------------------------------*/

static void sensor_monitor_entry(void *p1, void *p2, void *p3)
{
    (void)p1; (void)p2; (void)p3;

    LOG_INF("Sensor monitor started (%u ms interval).",
            (unsigned)SENSOR_MONITOR_INTERVAL_MS);

    while (true) {
        k_msleep(SENSOR_MONITOR_INTERVAL_MS);

        sensor_state_t local;
        k_mutex_lock(&s_sensor_lock, K_FOREVER);
        local = s_sensor_state;
        k_mutex_unlock(&s_sensor_lock);

        /* Reset valid flags — set them back on successful reads */
        local.status &= ~(uint8_t)(SENSOR_STATUS_TEMP_OK | SENSOR_STATUS_VOLTAGE_OK);

        /* Read temperature */
        int16_t temp_deg_c = 0;
        if (read_temperature(&temp_deg_c)) {
            local.temp_deg_c = temp_deg_c;
            local.status |= SENSOR_STATUS_TEMP_OK;
            LOG_DBG("Temperature: %d °C", (int)temp_deg_c);
        } else {
            LOG_WRN("Temperature sensor unavailable.");
        }

        /* Read voltage */
        uint16_t voltage_mv = 0U;
        if (read_voltage(&voltage_mv)) {
            local.voltage_mv = voltage_mv;
            local.status |= SENSOR_STATUS_VOLTAGE_OK;
            LOG_DBG("Voltage: %u mV", (unsigned)voltage_mv);
        } else {
            LOG_WRN("Voltage sensor unavailable.");
        }

        /* Threshold check and DTC update */
        check_thresholds(&local);

        /* Write back under lock */
        k_mutex_lock(&s_sensor_lock, K_FOREVER);
        s_sensor_state = local;
        k_mutex_unlock(&s_sensor_lock);
    }
}

/* ---------------------------------------------------------------------------
 * Public API
 * ---------------------------------------------------------------------------*/

void sensor_monitor_init(void)
{
    /* Initialise shared state with defaults */
    k_mutex_init(&s_sensor_lock);

    s_sensor_state.temp_deg_c               = 25;   /* assume room temp at boot */
    s_sensor_state.voltage_mv               = 12000U; /* assume nominal 12 V */
    s_sensor_state.status                   = 0U;
    s_sensor_state.temp_threshold_high_deg_c = SENSOR_TEMP_THRESHOLD_HIGH_DEFAULT_DEG_C;
    s_sensor_state.temp_threshold_low_deg_c  = SENSOR_TEMP_THRESHOLD_LOW_DEFAULT_DEG_C;

    /* Resolve sensor devices from Device Tree aliases */
#if DT_NODE_EXISTS(DT_ALIAS(temp_sensor_0))
    s_temp_dev = DEVICE_DT_GET(DT_ALIAS(temp_sensor_0));
    if (!device_is_ready(s_temp_dev)) {
        LOG_WRN("Temperature sensor not ready: %s", s_temp_dev->name);
        s_temp_dev = NULL;
    } else {
        LOG_INF("Temperature sensor: %s", s_temp_dev->name);
    }
#else
    LOG_WRN("No 'temp-sensor-0' alias in DTS — temperature sensor disabled.");
#endif

#if DT_NODE_EXISTS(DT_ALIAS(voltage_sensor_0))
    s_voltage_dev = DEVICE_DT_GET(DT_ALIAS(voltage_sensor_0));
    if (!device_is_ready(s_voltage_dev)) {
        LOG_WRN("Voltage sensor not ready: %s", s_voltage_dev->name);
        s_voltage_dev = NULL;
    } else {
        LOG_INF("Voltage sensor: %s", s_voltage_dev->name);
    }
#else
    LOG_WRN("No 'voltage-sensor-0' alias in DTS — voltage sensor disabled.");
#endif

    /* Start monitor thread */
    k_thread_create(
        &s_monitor_thread,
        s_monitor_stack,
        K_THREAD_STACK_SIZEOF(s_monitor_stack),
        sensor_monitor_entry,
        NULL, NULL, NULL,
        SENSOR_MONITOR_PRIORITY,
        0U,
        K_NO_WAIT
    );
    k_thread_name_set(&s_monitor_thread, "sensor_monitor");
}

void sensor_state_get(sensor_state_t *out)
{
    k_mutex_lock(&s_sensor_lock, K_FOREVER);
    *out = s_sensor_state;
    k_mutex_unlock(&s_sensor_lock);
}

void sensor_set_temp_threshold_high(int8_t deg_c)
{
    k_mutex_lock(&s_sensor_lock, K_FOREVER);
    s_sensor_state.temp_threshold_high_deg_c = deg_c;
    k_mutex_unlock(&s_sensor_lock);
    LOG_INF("Temp threshold high set to %d °C", (int)deg_c);
}

void sensor_set_temp_threshold_low(int8_t deg_c)
{
    k_mutex_lock(&s_sensor_lock, K_FOREVER);
    s_sensor_state.temp_threshold_low_deg_c = deg_c;
    k_mutex_unlock(&s_sensor_lock);
    LOG_INF("Temp threshold low set to %d °C", (int)deg_c);
}
```
